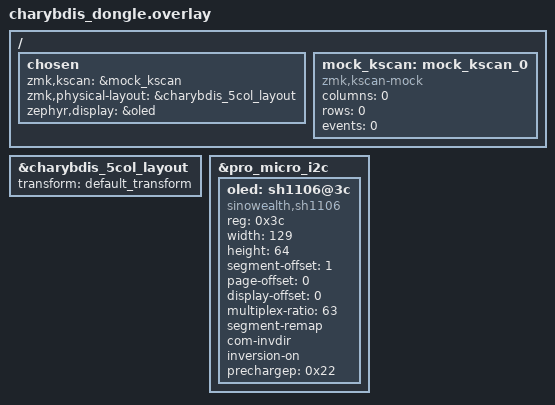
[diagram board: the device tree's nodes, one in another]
#include "charybdis.dtsi"
#include <dt-bindings/zmk/matrix_transform.h>


&charybdis_5col_layout {
    transform = <&default_transform>;
};

/ {
    chosen {
        zmk,kscan = &mock_kscan;
        zmk,physical-layout = &charybdis_5col_layout;
        zephyr,display = &oled;
    };

    mock_kscan: mock_kscan_0 {
        compatible = "zmk,kscan-mock";
        columns = <0>;
        rows = <0>;
        events = <0>;
    };
};
&pro_micro_i2c {
    status = "okay";
    oled: sh1106@3c {
        compatible = "sinowealth,sh1106";
        reg = <0x3c>;
        width = <129>;
        height = <64>;
        segment-offset = <1>;
        page-offset = <0>;
        display-offset = <0>;
        multiplex-ratio = <63>;
        segment-remap;
        com-invdir;
        inversion-on;
        prechargep = <0x22>;
    };
};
